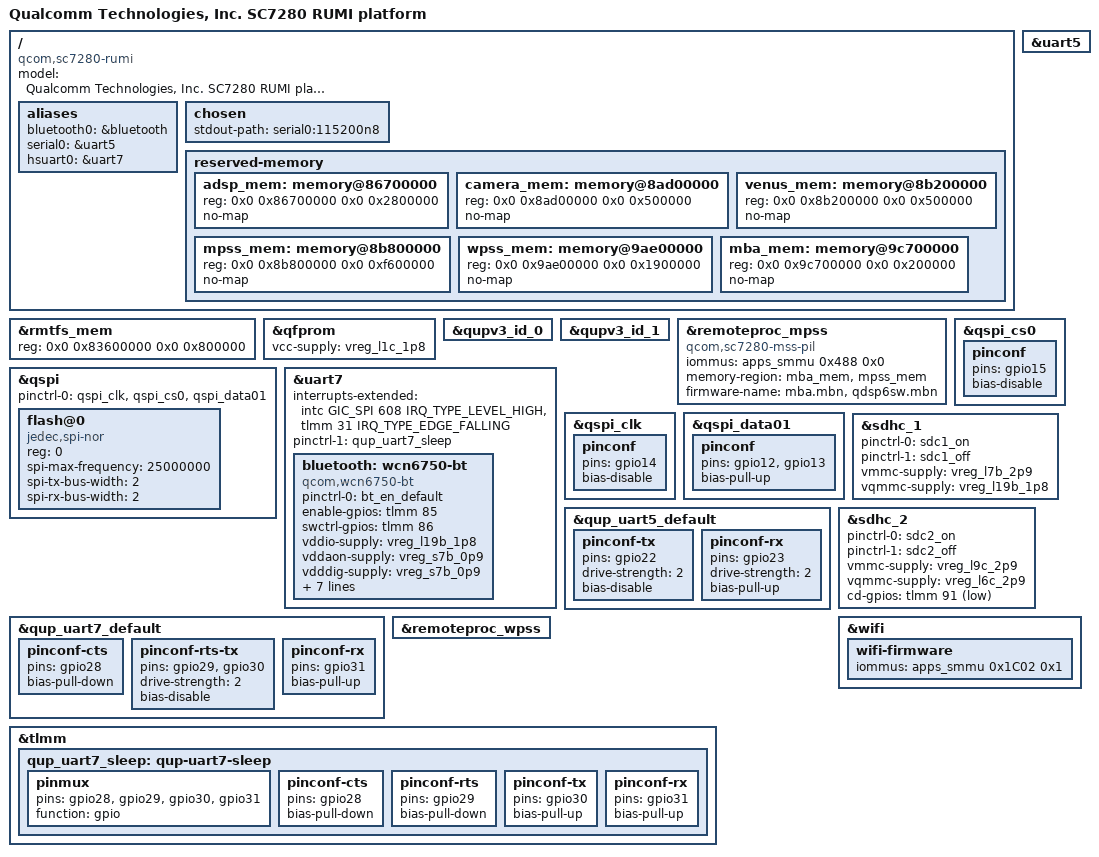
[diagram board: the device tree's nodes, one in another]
// SPDX-License-Identifier: BSD-3-Clause
/*
 * sc7280 IDP board device tree source
 *
 * Copyright (c) 2020, The Linux Foundation. All rights reserved.
 */

/dts-v1/;

#include <dt-bindings/gpio/gpio.h>
#include "sc7280.dtsi"

/ {
	model = "Qualcomm Technologies, Inc. SC7280 RUMI platform";
	compatible = "qcom,sc7280-rumi";

	aliases {
		bluetooth0 = &bluetooth;
		serial0 = &uart5;
		hsuart0 = &uart7;
	};

	chosen {
		stdout-path = "serial0:115200n8";
	};
};

/*
 * Reserved memory changes
 *
 * Delete all unused memory nodes and define the peripheral memory regions
 * required by the board dts.
 *
 */

/delete-node/ &hyp_mem;
/delete-node/ &xbl_mem;
/delete-node/ &sec_apps_mem;

/* Increase the size from 2MB to 8MB */
&rmtfs_mem {
	reg = <0x0 0x83600000 0x0 0x800000>;
};

/ {
	reserved-memory {
		adsp_mem: memory@86700000 {
			reg = <0x0 0x86700000 0x0 0x2800000>;
			no-map;
		};

		camera_mem: memory@8ad00000 {
			reg = <0x0 0x8ad00000 0x0 0x500000>;
			no-map;
		};

		venus_mem: memory@8b200000 {
			reg = <0x0 0x8b200000 0x0 0x500000>;
			no-map;
		};

		mpss_mem: memory@8b800000 {
			reg = <0x0 0x8b800000 0x0 0xf600000>;
			no-map;
		};

		wpss_mem: memory@9ae00000 {
			reg = <0x0 0x9ae00000 0x0 0x1900000>;
			no-map;
		};

		mba_mem: memory@9c700000 {
			reg = <0x0 0x9c700000 0x0 0x200000>;
			no-map;
		};
	};
};

&qfprom {
	vcc-supply = <&vreg_l1c_1p8>;
};

&qupv3_id_0 {
	status = "okay";
};

&qupv3_id_1 {
	status = "okay";
};

&remoteproc_mpss {
	status = "okay";
	compatible = "qcom,sc7280-mss-pil";
	iommus = <&apps_smmu 0x488 0x0>;
	memory-region = <&mba_mem &mpss_mem>;
	firmware-name = "mba.mbn", "qdsp6sw.mbn";
};

&qspi {
	status = "okay";
	pinctrl-names = "default";
	pinctrl-0 = <&qspi_clk>, <&qspi_cs0>, <&qspi_data01>;

	flash@0 {
		compatible = "jedec,spi-nor";
		reg = <0>;

		/* TODO: Increase frequency after testing */
		spi-max-frequency = <25000000>;
		spi-tx-bus-width = <2>;
		spi-rx-bus-width = <2>;
	};
};

&uart5 {
	status = "okay";
};

&uart7 {
	status = "okay";

	/delete-property/interrupts;
	interrupts-extended = <&intc GIC_SPI 608 IRQ_TYPE_LEVEL_HIGH>,
				<&tlmm 31 IRQ_TYPE_EDGE_FALLING>;
	pinctrl-names = "default", "sleep";
	pinctrl-1 = <&qup_uart7_sleep>;

	bluetooth: wcn6750-bt {
		compatible = "qcom,wcn6750-bt";
		pinctrl-names = "default";
		pinctrl-0 = <&bt_en_default>;
		enable-gpios = <&tlmm 85 GPIO_ACTIVE_HIGH>; /* BT_EN */
		swctrl-gpios = <&tlmm 86 GPIO_ACTIVE_HIGH>; /* SW_CTRL */
		vddio-supply = <&vreg_l19b_1p8>;  /* IO */
		vddaon-supply = <&vreg_s7b_0p9>;
		vdddig-supply = <&vreg_s7b_0p9>;
		vddrfacmn-supply = <&vreg_s7b_0p9>;
		vddrfa0p8-supply = <&vreg_s7b_0p9>;
		vddrfa1-supply = <&vreg_s1b_1p8>; /*RFA 1p7*/
		vddrfa2-supply = <&vreg_s8b_1p2>; /*RFA 1p2*/
		vddipa2p2-supply = <&vreg_s1c_2p2>; /*IPA 2p2*/
		vddasd-supply = <&vreg_l11c_2p8>;
		max-speed = <3000000>;
	};

};

/* PINCTRL - additions to nodes defined in sc7280.dtsi */

&qspi_cs0 {
	pinconf {
		pins = "gpio15";
		bias-disable;
	};
};

&qspi_clk {
	pinconf {
		pins = "gpio14";
		bias-disable;
	};
};

&qspi_data01 {
	pinconf {
		pins = "gpio12", "gpio13";

		/* High-Z when no transfers; nice to park the lines */
		bias-pull-up;
	};
};

&qup_uart5_default {
	pinconf-tx {
		pins = "gpio22";
		drive-strength = <2>;
		bias-disable;
	};

	pinconf-rx {
		pins = "gpio23";
		drive-strength = <2>;
		bias-pull-up;
	};
};

&sdhc_1 {
	status = "okay";


	pinctrl-names = "default", "sleep";
	pinctrl-0 = <&sdc1_on>;
	pinctrl-1 = <&sdc1_off>;

	vmmc-supply = <&vreg_l7b_2p9>;
	vqmmc-supply = <&vreg_l19b_1p8>;


};

&sdhc_2 {
	status = "okay";


	pinctrl-names = "default","sleep";
	pinctrl-0 = <&sdc2_on>;
	pinctrl-1 = <&sdc2_off>;

	vmmc-supply = <&vreg_l9c_2p9>;
	vqmmc-supply = <&vreg_l6c_2p9>;



	cd-gpios = <&tlmm 91 GPIO_ACTIVE_LOW>;

};

&qup_uart7_default {
	pinconf-cts {
		/*
		 * Configure a pull-down on CTS to match the pull of
		 * the Bluetooth module.
		 */
		pins = "gpio28";
		bias-pull-down;
	};

	pinconf-rts-tx {
		/* We'll drive RTS and TX, so no pull */
		pins = "gpio29", "gpio30";
		drive-strength = <2>;
		bias-disable;
	};

	pinconf-rx {
		/*
		 * Configure a pull-up on RX. This is needed to avoid
		 * garbage data when the TX pin of the Bluetooth module is
		 * in tri-state (module powered off or not driving the
		 * signal yet).
		 */
		pins = "gpio31";
		bias-pull-up;
	};
};

&remoteproc_wpss {
	status = "okay";
};

&wifi {
	status = "okay";
	wifi-firmware {
		iommus = <&apps_smmu 0x1C02 0x1>;
	};
};

&tlmm {
	qup_uart7_sleep: qup-uart7-sleep {
		pinmux {
			pins = "gpio28", "gpio29",
			       "gpio30", "gpio31";
			function = "gpio";
		};

		pinconf-cts {
			/*
			 * Configure a pull-down on CTS to match the pull of
			 * the Bluetooth module.
			 */
			pins = "gpio28";
			bias-pull-down;
		};

		pinconf-rts {
			/*
			 * Configure pull-down on RTS. As RTS is active low
			 * signal, pull it low to indicate the BT SoC that it
			 * can wakeup the system anytime from suspend state by
			 * pulling RX low (by sending wakeup bytes).
			 */
			 pins = "gpio29";
			 bias-pull-down;
		};

		pinconf-tx {
			/*
			 * Configure pull-up on TX when it isn't actively driven
			 * to prevent BT SoC from receiving garbage during sleep.
			 */
			pins = "gpio30";
			bias-pull-up;
		};

		pinconf-rx {
			/*
			 * Configure a pull-up on RX. This is needed to avoid
			 * garbage data when the TX pin of the Bluetooth module
			 * is floating which may cause spurious wakeups.
			 */
			pins = "gpio31";
			bias-pull-up;
		};
	};
};
